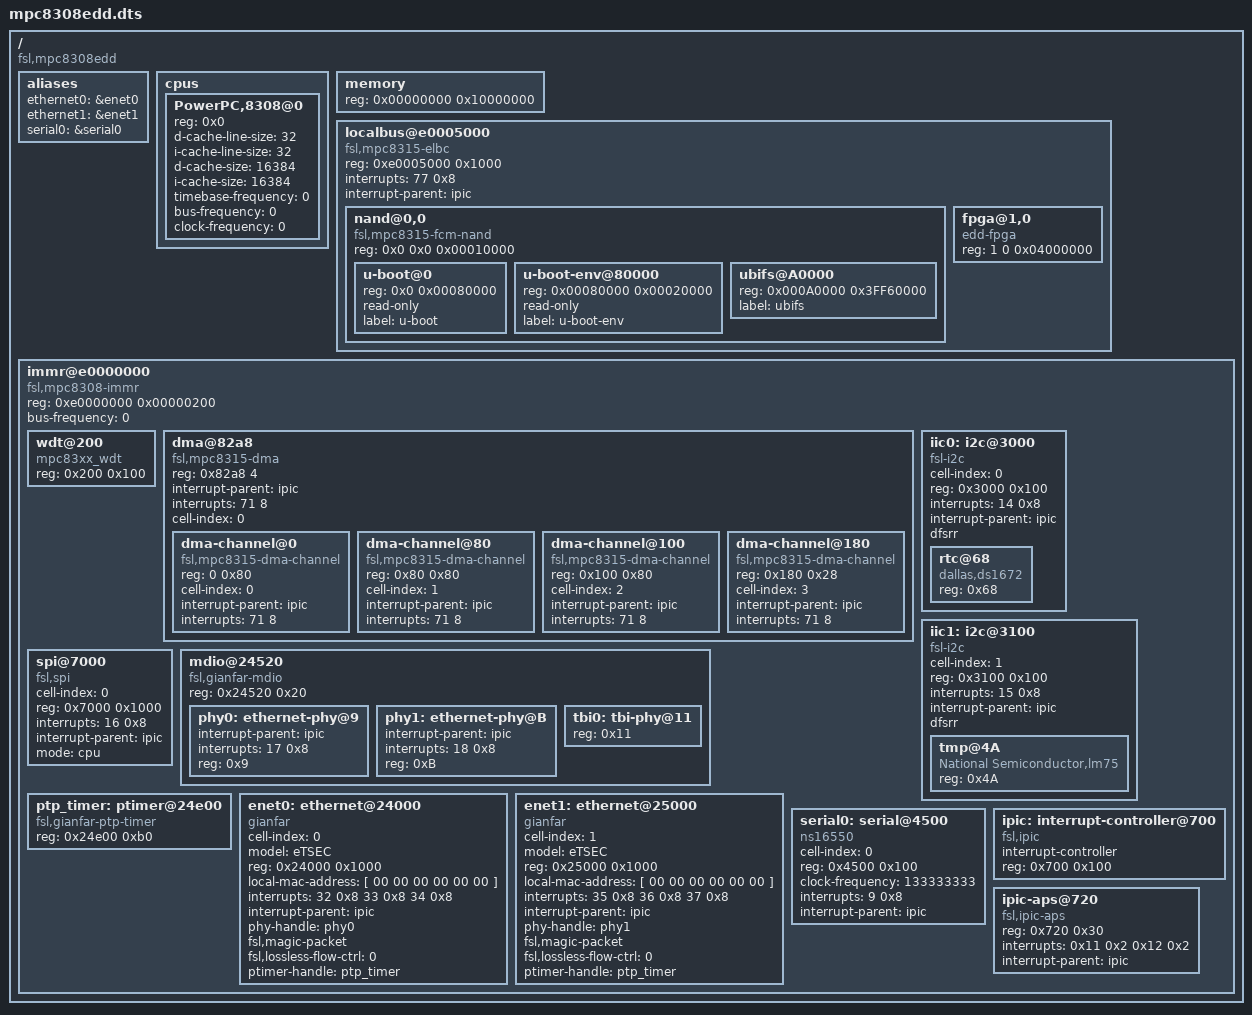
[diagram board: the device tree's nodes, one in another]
/*
 * MPC8308edd Device Tree Source
 *
 * Copyright 2009 Freescale Semiconductor Inc.
 *
 * This program is free software; you can redistribute  it and/or modify it
 * under  the terms of  the GNU General  Public License as published by the
 * Free Software Foundation;  either version 2 of the  License, or (at your
 * option) any later version.
 */

/dts-v1/;

/ {
	compatible = "fsl,mpc8308edd";
	#address-cells = <1>;
	#size-cells = <1>;

	aliases {
		ethernet0 = &enet0;
		ethernet1 = &enet1;
		serial0 = &serial0;
	};

	cpus {
		#address-cells = <1>;
		#size-cells = <0>;

		PowerPC,8308@0 {
			device_type = "cpu";
			reg = <0x0>;
			d-cache-line-size = <32>;
			i-cache-line-size = <32>;
			d-cache-size = <16384>;
			i-cache-size = <16384>;
			timebase-frequency = <0>;	// from bootloader
			bus-frequency = <0>;		// from bootloader
			clock-frequency = <0>;		// from bootloader
		};
	};

	memory {
		device_type = "memory";
		reg = <0x00000000 0x10000000>;	// 256MB at 0
	};

	localbus@e0005000 {
		#address-cells = <2>;
		#size-cells = <1>;
		compatible = "fsl,mpc8315-elbc", "fsl,elbc", "simple-bus";
		reg = <0xe0005000 0x1000>;
		interrupts = <77 0x8>;
		interrupt-parent = <&ipic>;


		ranges = <0x0 0x0 0xe0600000 0x00010000			// NAND FLASH 0
		          0x1 0x0 0xf0000000 0x04000000			// FPGA
		          0x2 0x0 0xfa000000 0x00008000>;	

		nand@0,0 {
			#address-cells = <1>;
			#size-cells = <1>;
			compatible = "fsl,mpc8315-fcm-nand",
			             "fsl,elbc-fcm-nand";
			reg = <0x0 0x0 0x00010000>;

			u-boot@0 {
				reg = <0x0 0x00080000>;
				read-only;
				label = "u-boot";
			};
			u-boot-env@80000 {
				reg = <0x00080000 0x00020000>;
				read-only;
				label = "u-boot-env";
			};
			ubifs@A0000 {
				reg = <0x000A0000 0x3FF60000>;
				label = "ubifs";
			};
		};
		fpga@1,0 {
			compatible = "edd-fpga";
			reg = <1 0 0x04000000>;
		};
	};

	immr@e0000000 {
		#address-cells = <1>;
		#size-cells = <1>;
		device_type = "soc";
		compatible = "fsl,mpc8308-immr", "simple-bus";
		ranges = <0 0xe0000000 0x00100000>;
		reg = <0xe0000000 0x00000200>;
		bus-frequency = <0>;

		wdt@200 {
			device_type = "watchdog";
			compatible = "mpc83xx_wdt";
			reg = <0x200 0x100>;
		};

		dma@82a8 {
			#address-cells = <1>;
			#size-cells = <1>;
			compatible = "fsl,mpc8315-dma", "fsl,elo-dma";
			reg = <0x82a8 4>;
			ranges = <0 0x8100 0x1a8>;
			interrupt-parent = <&ipic>;
			interrupts = <71 8>;
			cell-index = <0>;
			dma-channel@0 {
				compatible = "fsl,mpc8315-dma-channel", "fsl,elo-dma-channel";
				reg = <0 0x80>;
				cell-index = <0>;
				interrupt-parent = <&ipic>;
				interrupts = <71 8>;
			};
			dma-channel@80 {
				compatible = "fsl,mpc8315-dma-channel", "fsl,elo-dma-channel";
				reg = <0x80 0x80>;
				cell-index = <1>;
				interrupt-parent = <&ipic>;
				interrupts = <71 8>;
			};
			dma-channel@100 {
				compatible = "fsl,mpc8315-dma-channel", "fsl,elo-dma-channel";
				reg = <0x100 0x80>;
				cell-index = <2>;
				interrupt-parent = <&ipic>;
				interrupts = <71 8>;
			};
			dma-channel@180 {
				compatible = "fsl,mpc8315-dma-channel", "fsl,elo-dma-channel";
				reg = <0x180 0x28>;
				cell-index = <3>;
				interrupt-parent = <&ipic>;
				interrupts = <71 8>;
			};
		};

		iic0: i2c@3000 {
			#address-cells = <1>;
			#size-cells = <0>;
			cell-index = <0>;
			compatible = "fsl-i2c";
			reg = <0x3000 0x100>;
			interrupts = <14 0x8>;
			interrupt-parent = <&ipic>;
			dfsrr;
			rtc@68 {
				compatible = "dallas,ds1672";
				reg = <0x68>;
				};
			};
		iic1: i2c@3100 {
			#address-cells = <1>;
			#size-cells = <0>;
			cell-index = <1>;
			compatible = "fsl-i2c";
			reg = <0x3100 0x100>;
			interrupts = <15 0x8>;
			interrupt-parent = <&ipic>;
			dfsrr;
/*			tmp@48 {
				compatible = "National Semiconductor,lm75";
				reg = <0x48>;
				};
*/
			tmp@4A {
				compatible = "National Semiconductor,lm75";
				reg = <0x4A>;
				};
			};

		spi@7000 {
			cell-index = <0>;
			compatible = "fsl,spi";
			reg = <0x7000 0x1000>;
			interrupts = <16 0x8>;
			interrupt-parent = <&ipic>;
			mode = "cpu";
			};

		mdio@24520 {
			#address-cells = <1>;
			#size-cells = <0>;
			compatible = "fsl,gianfar-mdio";
			reg = <0x24520 0x20>;
			phy0: ethernet-phy@9 {
				interrupt-parent = <&ipic>;
				interrupts = <17 0x8>;
				reg = <0x9>;
				device_type = "ethernet-phy";
			};
			
			phy1: ethernet-phy@B {
				interrupt-parent = <&ipic>;
				interrupts = <18 0x8>;
				reg = <0xB>;
				device_type = "ethernet-phy";
			};

			tbi0: tbi-phy@11 {
				reg = <0x11>;
				device_type = "tbi-phy";
			};
		};

		ptp_timer: ptimer@24e00 {
			compatible = "fsl,gianfar-ptp-timer";
			reg = <0x24e00 0xb0>;
		};

		enet0: ethernet@24000 {
			cell-index = <0>;
			device_type = "network";
			model = "eTSEC";
			compatible = "gianfar";
			reg = <0x24000 0x1000>;
			local-mac-address = [ 00 00 00 00 00 00 ];
			interrupts = <32 0x8 33 0x8 34 0x8>;
			interrupt-parent = <&ipic>;
/*			tbi-handle = <&tbi0>;    */
			phy-handle = < &phy0 >;
/*			sleep = <&pmc 0xc0000000>;	*/
			fsl,magic-packet;
			fsl,lossless-flow-ctrl = <0>;
			ptimer-handle = < &ptp_timer >;
		};

		enet1: ethernet@25000 {
			cell-index = <1>;
			device_type = "network";
			model = "eTSEC";
			compatible = "gianfar";
			reg = <0x25000 0x1000>;
			local-mac-address = [ 00 00 00 00 00 00 ];
			interrupts = <35 0x8 36 0x8 37 0x8>;
			interrupt-parent = <&ipic>;
/*			tbi-handle = <&tbi1>;     */
			phy-handle = < &phy1 >;
			/* Vitesse 7385 isn't on the MDIO bus */
/*			fixed-link = <1 1 100 0 0>;   */
/*			sleep = <&pmc 0x30000000>;	*/
			fsl,magic-packet;
			fsl,lossless-flow-ctrl = <0>;
			ptimer-handle = < &ptp_timer >;
/*			phy-connection-type = "rgmii-id";   */
		};

		serial0: serial@4500 {
			cell-index = <0>;
			device_type = "serial";
			compatible = "ns16550";
			reg = <0x4500 0x100>;
			clock-frequency = <133333333>;
			interrupts = <9 0x8>;
			interrupt-parent = <&ipic>;
		};

		/*gpio@c00 {
			device_type = "gpio";
			compatible = "fsl,mpc8315-gpio";
			reg = <0xc00 0x18>;
			interrupt-parent = < &ipic >;
		};*/

		/* IPIC
		 * interrupts cell = <intr #, sense>
		 * sense values match linux IORESOURCE_IRQ_* defines:
		 * sense == 8: Level, low assertion
		 * sense == 2: Edge, high-to-low change
		 */
		ipic: interrupt-controller@700 {
			compatible = "fsl,ipic";
			interrupt-controller;
			#address-cells = <0>;
			#interrupt-cells = <2>;
			reg = <0x700 0x100>;
			device_type = "ipic";
		};

		ipic-aps@720 {
			compatible = "fsl,ipic-aps";
			reg = <0x720 0x30>;
			interrupts = < 0x11 0x2
				       0x12 0x2>;
			interrupt-parent = < &ipic >;
		};
/*
		ipic-msi@7c0 {
			compatible = "fsl,ipic-msi";
			reg = <0x7c0 0x40>;
			msi-available-ranges = <0x0 0x100>;
			interrupts = < 0x43 0x8
					0x4  0x8
					0x51 0x8
					0x52 0x8
					0x56 0x8
					0x57 0x8
					0x58 0x8
					0x59 0x8 >;
			interrupt-parent = < &ipic >;
		};
*/
/*		pmc: power@b00 {
			compatible = "fsl,mpc8313-pmc", "fsl,mpc8349-pmc";
			reg = <0xb00 0x100 0xa00 0x100>;
			interrupts = <80 8>;
			interrupt-parent = <&ipic>;
			fsl,mpc8313-wakeup-timer = <&gtm1>;
		};
*/
/*		gtm1: timer@500 {
			compatible = "fsl,mpc8313-gtm", "fsl,gtm";
			reg = <0x500 0x100>;
			clock-frequency = <133000000>;
			interrupts = <90 8 78 8 84 8 72 8>;
			interrupt-parent = <&ipic>;
		};
*/
	};
	
/*	pci0: pcie@e0009000 {
		#address-cells = <3>;
		#size-cells = <2>;
		#interrupt-cells = <1>;
		device_type = "pci";
		compatible = "fsl,mpc8308-pcie", "fsl,mpc8314-pcie";
		reg = <0xe0009000 0x00001000
			0xb0000000 0x01000000>;
		ranges = <0x02000000 0 0xa0000000 0xa0000000 0 0x10000000
		          0x01000000 0 0x00000000 0xb1000000 0 0x00800000>;
		bus-range = <0 0>;
		interrupt-map-mask = <0 0 0 0>;
		interrupt-map = <0 0 0 0 &ipic 1 8>;
		interrupts = <0x1 0x8>;
		interrupt-parent = <&ipic>;
		clock-frequency = <0>;

		pcie@0 {
			#address-cells = <3>;
			#size-cells = <2>;
			device_type = "pci";
			reg = <0 0 0 0 0>;
			ranges = <0x02000000 0 0xa0000000
				  0x02000000 0 0xa0000000
				  0 0x10000000
				  0x01000000 0 0x00000000
				  0x01000000 0 0x00000000
				  0 0x00800000>;
		};
	};
*/
};
